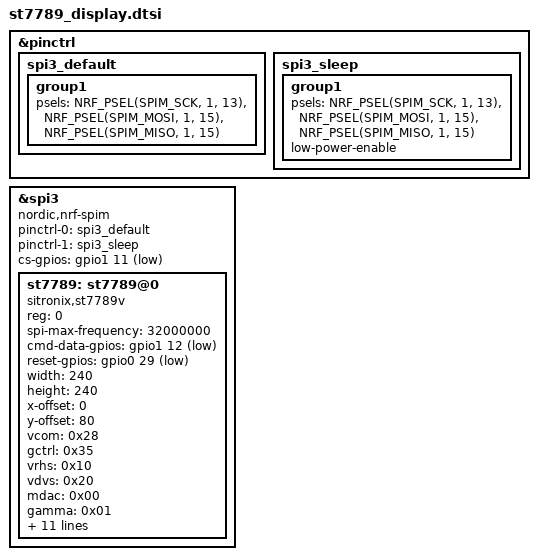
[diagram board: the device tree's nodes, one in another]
/*
 * ST7789 Display Configuration for xiao_ble with Zephyr 3.5
 * This provides the st7789 display node referenced by prospector_adapter
 * Uses SPI3 peripheral (SPI0 is used by trackball)
 */

&pinctrl {
    spi3_default: spi3_default {
        group1 {
            psels = <NRF_PSEL(SPIM_SCK, 1, 13)>,
                <NRF_PSEL(SPIM_MOSI, 1, 15)>,
                <NRF_PSEL(SPIM_MISO, 1, 15)>;
        };
    };

    spi3_sleep: spi3_sleep {
        group1 {
            psels = <NRF_PSEL(SPIM_SCK, 1, 13)>,
                <NRF_PSEL(SPIM_MOSI, 1, 15)>,
                <NRF_PSEL(SPIM_MISO, 1, 15)>;
            low-power-enable;
        };
    };
};

&spi3 {
    status = "okay";
    compatible = "nordic,nrf-spim";
    pinctrl-0 = <&spi3_default>;
    pinctrl-1 = <&spi3_sleep>;
    pinctrl-names = "default", "sleep";
    cs-gpios = <&gpio1 11 GPIO_ACTIVE_LOW>;

    st7789: st7789@0 {
        compatible = "sitronix,st7789v";
        reg = <0>;
        spi-max-frequency = <32000000>;
        cmd-data-gpios = <&gpio1 12 GPIO_ACTIVE_LOW>;
        reset-gpios = <&gpio0 29 GPIO_ACTIVE_LOW>;
        width = <240>;
        height = <240>;
        x-offset = <0>;
        y-offset = <80>;
        vcom = <0x28>;
        gctrl = <0x35>;
        vrhs = <0x10>;
        vdvs = <0x20>;
        mdac = <0x00>;
        gamma = <0x01>;
        colmod = <0x55>;
        lcm = <0x2c>;
        porch-param = [0c 0c 00 33 33];
        cmd2en-param = [5a 69 02 01];
        pwctrl1-param = [52 a1];
        pvgam-param = [D0 00 02 07 0B 1A 31 54 40 29 12 12 12 17];
        nvgam-param = [D0 00 02 07 05 25 2D 44 45 1C 18 16 1C 1D];
        ram-param = [00 F8];
        rgb-param = [CD 08 14];
    };
};
